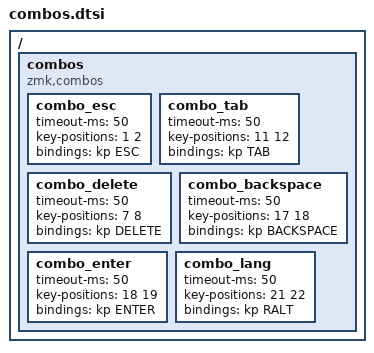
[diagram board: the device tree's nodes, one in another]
/ {
  combos {
    compatible = "zmk,combos";
    combo_esc {
      timeout-ms = <50>;
      key-positions = <1 2>;
      bindings = <&kp ESC>;
    };
    combo_tab {
      timeout-ms = <50>;
      key-positions = <11 12>;
      bindings = <&kp TAB>;
    };
    combo_delete {
      timeout-ms = <50>;
      key-positions = <7 8>;
      bindings = <&kp DELETE>;
    };
    combo_backspace {
      timeout-ms = <50>;
      key-positions = <17 18>;
      bindings = <&kp BACKSPACE>;
    };
    combo_enter {
      timeout-ms = <50>;
      key-positions = <18 19>;
      bindings = <&kp ENTER>;
    };
    combo_lang {
      timeout-ms = <50>;
      key-positions = <21 22>;
      bindings = <&kp RALT>;
    };
  };
};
